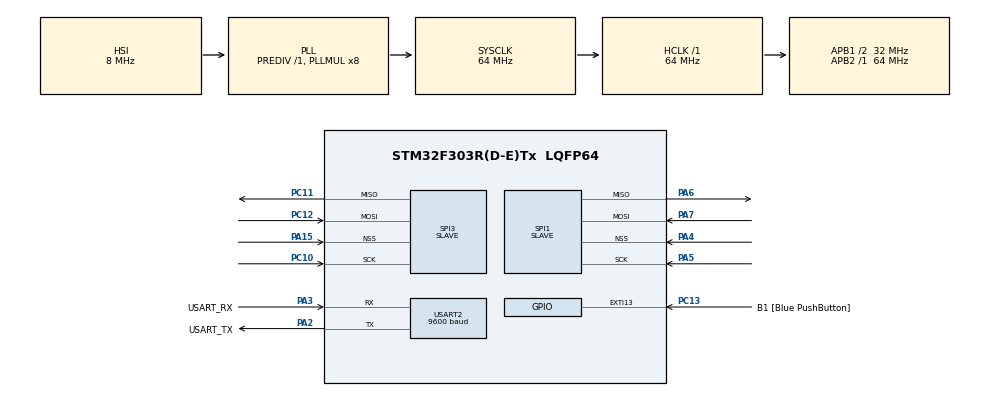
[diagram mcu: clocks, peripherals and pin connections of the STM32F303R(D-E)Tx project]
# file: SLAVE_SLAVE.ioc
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Mcu.Family=STM32F3
Mcu.Name=STM32F303R(D-E)Tx
Mcu.Package=LQFP64
NVIC.PriorityGroup=NVIC_PRIORITYGROUP_0
NVIC.SPI1_IRQn=true\:0\:0\:false\:false\:true\:true\:true\:true
NVIC.SPI3_IRQn=true\:0\:0\:false\:false\:true\:true\:true\:true
NVIC.USART2_IRQn=true\:0\:0\:false\:false\:true\:true\:true\:true
PA13.GPIO_Label=TMS
PA13.Signal=SYS_JTMS-SWDIO
PA14.GPIO_Label=TCK
PA14.Signal=SYS_JTCK-SWCLK
PA15.Mode=NSS_Signal_Hard_Input
PA15.Signal=SPI3_NSS
PA2.GPIO_Label=USART_TX
PA2.GPIO_Mode=GPIO_MODE_AF_PP
PA2.GPIO_PuPd=GPIO_NOPULL
PA2.GPIO_Speed=GPIO_SPEED_FREQ_LOW
PA2.Mode=Asynchronous
PA2.Signal=USART2_TX
PA3.GPIO_Label=USART_RX
PA3.GPIO_Mode=GPIO_MODE_AF_PP
PA3.GPIO_PuPd=GPIO_NOPULL
PA3.GPIO_Speed=GPIO_SPEED_FREQ_LOW
PA3.Mode=Asynchronous
PA3.Signal=USART2_RX
PA4.Mode=NSS_Signal_Hard_Input
PA4.Signal=SPI1_NSS
PA5.Mode=Full_Duplex_Slave
PA5.Signal=SPI1_SCK
PA6.Mode=Full_Duplex_Slave
PA6.Signal=SPI1_MISO
PA7.Mode=Full_Duplex_Slave
PA7.Signal=SPI1_MOSI
PB3.GPIO_Label=SWO
PB3.Signal=SYS_JTDO-TRACESWO
PC10.Mode=Full_Duplex_Slave
PC10.Signal=SPI3_SCK
PC11.Mode=Full_Duplex_Slave
PC11.Signal=SPI3_MISO
PC12.Mode=Full_Duplex_Slave
PC12.Signal=SPI3_MOSI
PC13.GPIO_Label=B1 [Blue PushButton]
PC13.GPIO_ModeDefaultEXTI=GPIO_MODE_IT_FALLING
PC13.Signal=GPXTI13
PC14-OSC32_IN.Signal=RCC_OSC32_IN
PC15-OSC32_OUT.Signal=RCC_OSC32_OUT
PF0-OSC_IN.Signal=RCC_OSC_IN
PF1-OSC_OUT.Signal=RCC_OSC_OUT
ProjectManager.HeapSize=0x200
ProjectManager.StackSize=0x400
ProjectManager.TargetToolchain=STM32CubeIDE
RCC.AHBFreq_Value=64000000
RCC.APB1CLKDivider=RCC_HCLK_DIV2
RCC.APB1Freq_Value=32000000
RCC.APB1TimFreq_Value=64000000
RCC.APB2Freq_Value=64000000
RCC.APB2TimFreq_Value=64000000
RCC.CortexFreq_Value=64000000
RCC.HCLKFreq_Value=64000000
RCC.HSE_VALUE=8000000
RCC.HSI_VALUE=8000000
RCC.LSE_VALUE=32768
RCC.PLLM=8
RCC.PLLMUL=RCC_PLL_MUL8
RCC.PLLN=336
RCC.PLLP=RCC_PLLP_DIV4
RCC.PLLQ=7
RCC.RCC_PLLsource_Clock_Source_FROM_HSE=RCC_HSE_PREDIV_DIV2
RCC.SYSCLKFreq_VALUE=64000000
RCC.SYSCLKSourceVirtual=RCC_SYSCLKSOURCE_PLLCLK
RCC.USBFreq_Value=64000000
SPI1.CLKPolarity=SPI_POLARITY_LOW
SPI1.DataSize=SPI_DATASIZE_8BIT
SPI1.Direction=SPI_DIRECTION_2LINES
SPI1.Mode=SPI_MODE_SLAVE
SPI1.VirtualNSS=VM_NSSHARD
SPI1.VirtualType=VM_SLAVE
SPI3.CLKPolarity=SPI_POLARITY_LOW
SPI3.DataSize=SPI_DATASIZE_8BIT
SPI3.Direction=SPI_DIRECTION_2LINES
SPI3.Mode=SPI_MODE_SLAVE
SPI3.VirtualNSS=VM_NSSHARD
SPI3.VirtualType=VM_SLAVE
USART2.BaudRate=9600
USART2.VirtualMode-Asynchronous=VM_ASYNC
board=NUCLEO-F303RE

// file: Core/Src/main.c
/* USER CODE BEGIN Header */
/**
  **************************
  * @file           : main.c
  * @brief          : Main program body
  **************************
  * @attention
  *
  * Copyright (c) 2024 STMicroelectronics.
  * All rights reserved.
  *
  * This software is licensed under terms that can be found in the LICENSE file
  * in the root directory of this software component.
  * If no LICENSE file comes with this software, it is provided AS-IS.
  *
  **************************
  */
/* USER CODE END Header */
#include "main.h"\
#include <stdio.h>

SPI_HandleTypeDef hspi1;
SPI_HandleTypeDef hspi3;

UART_HandleTypeDef huart2;

/* USER CODE BEGIN PV */
char uart_buf[50];
int uart_buf_len;
char spi_rx_buf1[11];  // Corregir la declaración
char spi_rx_buf3[11];  // Corregir la declaración

volatile uint8_t spi1_received = 0;
volatile uint8_t spi3_received = 0;
/* USER CODE END PV */

void SystemClock_Config(void);
static void MX_GPIO_Init(void);
static void MX_SPI1_Init(void);
static void MX_SPI3_Init(void);
static void MX_USART2_UART_Init(void);

int main(void)
{

  /* MCU Configuration--------------------------------------------------------*/

  /* Reset of all peripherals, Initializes the Flash interface and the Systick. */
  HAL_Init();

  /* Configure the system clock */
  SystemClock_Config();

  /* Initialize all configured peripherals */
  MX_GPIO_Init();
  MX_SPI1_Init();
  MX_SPI3_Init();
  MX_USART2_UART_Init();

  /* Initialize all configured peripherals */
   MX_GPIO_Init();
   MX_SPI1_Init();
   MX_SPI3_Init();
   MX_USART2_UART_Init();
   /* USER CODE BEGIN 2 */
   /* USER CODE BEGIN 2 */
   /* USER CODE BEGIN 2 */
   uart_buf_len = sprintf(uart_buf, "Esperando datos por SPI...\r\n");
   HAL_UART_Transmit(&huart2, (uint8_t *)uart_buf, uart_buf_len, HAL_MAX_DELAY);

   // Iniciar recepción por interrupción
   HAL_SPI_Receive_IT(&hspi1, (uint8_t *)spi_rx_buf1, sizeof(spi_rx_buf1) - 1);
   HAL_SPI_Receive_IT(&hspi3, (uint8_t *)spi_rx_buf3, sizeof(spi_rx_buf3) - 1);

   /* Infinite loop */
   while (1)
   {
     // Manejo de la recepción por SPI1
     if (spi1_received)
     {
       spi1_received = 0;
       Clear_UART_Buffer(&huart2);
       uart_buf_len = sprintf(uart_buf, "Datos recibidos por SPI1: %s\r\n", spi_rx_buf1);
       HAL_UART_Transmit(&huart2, (uint8_t *)uart_buf, uart_buf_len, HAL_MAX_DELAY);

       // Reiniciar recepción por interrupción
       HAL_SPI_Receive_IT(&hspi1, (uint8_t *)spi_rx_buf1, sizeof(spi_rx_buf1) - 1);
     }

     // Manejo de la recepción por SPI3
     if (spi3_received)
     {
       spi3_received = 0;
       Clear_UART_Buffer(&huart2);
       uart_buf_len = sprintf(uart_buf, "Datos recibidos por SPI3: %s\r\n", spi_rx_buf3);
       HAL_UART_Transmit(&huart2, (uint8_t *)uart_buf, uart_buf_len, HAL_MAX_DELAY);

       // Reiniciar recepción por interrupción
       HAL_SPI_Receive_IT(&hspi3, (uint8_t *)spi_rx_buf3, sizeof(spi_rx_buf3) - 1);
     }
   }
 }

 /* Callback para recepción de SPI1 */
 void HAL_SPI_RxCpltCallback(SPI_HandleTypeDef *hspi)
 {
   if (hspi->Instance == SPI1)
   {
     spi1_received = 1;
   }
   else if (hspi->Instance == SPI3)
   {
     spi3_received = 1;
   }
 }

 /* Función para limpiar el buffer de recepción del UART */
 void Clear_UART_Buffer(UART_HandleTypeDef *huart)
 {
   uint8_t temp;
   while (__HAL_UART_GET_FLAG(huart, UART_FLAG_RXNE))
   {
     temp = (uint8_t)(huart->Instance->RDR);
   }
 }

void SystemClock_Config(void)
{
  RCC_OscInitTypeDef RCC_OscInitStruct = {0};
  RCC_ClkInitTypeDef RCC_ClkInitStruct = {0};
  RCC_PeriphCLKInitTypeDef PeriphClkInit = {0};

  /** Initializes the RCC Oscillators according to the specified parameters
  * in the RCC_OscInitTypeDef structure.
  */
  RCC_OscInitStruct.OscillatorType = RCC_OSCILLATORTYPE_HSI;
  RCC_OscInitStruct.HSIState = RCC_HSI_ON;
  RCC_OscInitStruct.HSICalibrationValue = RCC_HSICALIBRATION_DEFAULT;
  RCC_OscInitStruct.PLL.PLLState = RCC_PLL_ON;
  RCC_OscInitStruct.PLL.PLLSource = RCC_PLLSOURCE_HSI;
  RCC_OscInitStruct.PLL.PLLMUL = RCC_PLL_MUL8;
  RCC_OscInitStruct.PLL.PREDIV = RCC_PREDIV_DIV1;
  if (HAL_RCC_OscConfig(&RCC_OscInitStruct) != HAL_OK)
  {
    Error_Handler();
  }

  /** Initializes the CPU, AHB and APB buses clocks
  */
  RCC_ClkInitStruct.ClockType = RCC_CLOCKTYPE_HCLK|RCC_CLOCKTYPE_SYSCLK
                              |RCC_CLOCKTYPE_PCLK1|RCC_CLOCKTYPE_PCLK2;
  RCC_ClkInitStruct.SYSCLKSource = RCC_SYSCLKSOURCE_PLLCLK;
  RCC_ClkInitStruct.AHBCLKDivider = RCC_SYSCLK_DIV1;
  RCC_ClkInitStruct.APB1CLKDivider = RCC_HCLK_DIV2;
  RCC_ClkInitStruct.APB2CLKDivider = RCC_HCLK_DIV1;

  if (HAL_RCC_ClockConfig(&RCC_ClkInitStruct, FLASH_LATENCY_2) != HAL_OK)
  {
    Error_Handler();
  }
  PeriphClkInit.PeriphClockSelection = RCC_PERIPHCLK_USART2;
  PeriphClkInit.Usart2ClockSelection = RCC_USART2CLKSOURCE_PCLK1;
  if (HAL_RCCEx_PeriphCLKConfig(&PeriphClkInit) != HAL_OK)
  {
    Error_Handler();
  }
}

static void MX_SPI1_Init(void)
{

  /* SPI1 parameter configuration*/
  hspi1.Instance = SPI1;
  hspi1.Init.Mode = SPI_MODE_SLAVE;
  hspi1.Init.Direction = SPI_DIRECTION_2LINES;
  hspi1.Init.DataSize = SPI_DATASIZE_8BIT;
  hspi1.Init.CLKPolarity = SPI_POLARITY_LOW;
  hspi1.Init.CLKPhase = SPI_PHASE_1EDGE;
  hspi1.Init.NSS = SPI_NSS_HARD_INPUT;
  hspi1.Init.FirstBit = SPI_FIRSTBIT_MSB;
  hspi1.Init.TIMode = SPI_TIMODE_DISABLE;
  hspi1.Init.CRCCalculation = SPI_CRCCALCULATION_DISABLE;
  hspi1.Init.CRCPolynomial = 7;
  hspi1.Init.CRCLength = SPI_CRC_LENGTH_DATASIZE;
  hspi1.Init.NSSPMode = SPI_NSS_PULSE_DISABLE;
  if (HAL_SPI_Init(&hspi1) != HAL_OK)
  {
    Error_Handler();
  }

}

static void MX_SPI3_Init(void)
{

  /* SPI3 parameter configuration*/
  hspi3.Instance = SPI3;
  hspi3.Init.Mode = SPI_MODE_SLAVE;
  hspi3.Init.Direction = SPI_DIRECTION_2LINES;
  hspi3.Init.DataSize = SPI_DATASIZE_8BIT;
  hspi3.Init.CLKPolarity = SPI_POLARITY_LOW;
  hspi3.Init.CLKPhase = SPI_PHASE_1EDGE;
  hspi3.Init.NSS = SPI_NSS_HARD_INPUT;
  hspi3.Init.FirstBit = SPI_FIRSTBIT_MSB;
  hspi3.Init.TIMode = SPI_TIMODE_DISABLE;
  hspi3.Init.CRCCalculation = SPI_CRCCALCULATION_DISABLE;
  hspi3.Init.CRCPolynomial = 7;
  hspi3.Init.CRCLength = SPI_CRC_LENGTH_DATASIZE;
  hspi3.Init.NSSPMode = SPI_NSS_PULSE_DISABLE;
  if (HAL_SPI_Init(&hspi3) != HAL_OK)
  {
    Error_Handler();
  }

}

static void MX_USART2_UART_Init(void)
{

  huart2.Instance = USART2;
  huart2.Init.BaudRate = 9600;
  huart2.Init.WordLength = UART_WORDLENGTH_8B;
  huart2.Init.StopBits = UART_STOPBITS_1;
  huart2.Init.Parity = UART_PARITY_NONE;
  huart2.Init.Mode = UART_MODE_TX_RX;
  huart2.Init.HwFlowCtl = UART_HWCONTROL_NONE;
  huart2.Init.OverSampling = UART_OVERSAMPLING_16;
  huart2.Init.OneBitSampling = UART_ONE_BIT_SAMPLE_DISABLE;
  huart2.AdvancedInit.AdvFeatureInit = UART_ADVFEATURE_NO_INIT;
  if (HAL_UART_Init(&huart2) != HAL_OK)
  {
    Error_Handler();
  }

}

static void MX_GPIO_Init(void)
{
  GPIO_InitTypeDef GPIO_InitStruct = {0};

  /* GPIO Ports Clock Enable */
  __HAL_RCC_GPIOC_CLK_ENABLE();
  __HAL_RCC_GPIOF_CLK_ENABLE();
  __HAL_RCC_GPIOA_CLK_ENABLE();
  __HAL_RCC_GPIOB_CLK_ENABLE();

  /*Configure GPIO pin : B1_Pin */
  GPIO_InitStruct.Pin = B1_Pin;
  GPIO_InitStruct.Mode = GPIO_MODE_IT_FALLING;
  GPIO_InitStruct.Pull = GPIO_NOPULL;
  HAL_GPIO_Init(B1_GPIO_Port, &GPIO_InitStruct);

}

void Error_Handler(void)
{
  __disable_irq();
  while (1)
  {
  }
}
